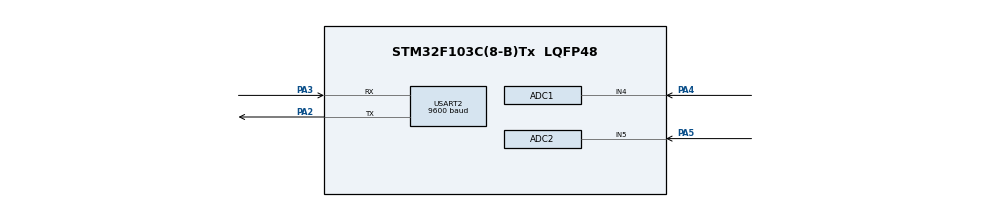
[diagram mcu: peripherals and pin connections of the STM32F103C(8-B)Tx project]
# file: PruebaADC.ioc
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ADC1.Channel-0\#ChannelRegularConversion=ADC_CHANNEL_4
ADC1.ContinuousConvMode=DISABLE
ADC1.DataAlign=ADC_DATAALIGN_RIGHT
ADC1.DiscontinuousConvMode=DISABLE
ADC1.EnableAnalogWatchDog=false
ADC1.EnableRegularConversion=ENABLE
ADC1.ExternalTrigConv=ADC_SOFTWARE_START
ADC1.InjNumberOfConversion=0
ADC1.NbrOfConversion=1
ADC1.NbrOfConversionFlag=1
ADC1.Rank-0\#ChannelRegularConversion=1
ADC1.SamplingTime-0\#ChannelRegularConversion=ADC_SAMPLETIME_1CYCLE_5
ADC1.ScanConvMode=ADC_SCAN_DISABLE
ADC1.master=1
ADC2.Channel-15\#ChannelRegularConversion=ADC_CHANNEL_5
ADC2.NbrOfConversionFlag=1
ADC2.Rank-15\#ChannelRegularConversion=1
ADC2.SamplingTime-15\#ChannelRegularConversion=ADC_SAMPLETIME_1CYCLE_5
Mcu.Family=STM32F1
Mcu.Name=STM32F103C(8-B)Tx
Mcu.Package=LQFP48
NVIC.ADC1_2_IRQn=true\:0\:0\:false\:false\:true\:true
NVIC.PriorityGroup=NVIC_PRIORITYGROUP_4
PA2.Mode=Asynchronous
PA2.Signal=USART2_TX
PA3.Mode=Asynchronous
PA3.Signal=USART2_RX
PA4.Signal=ADCx_IN4
PA5.Signal=ADCx_IN5
ProjectManager.HeapSize=0x200
ProjectManager.StackSize=0x400
ProjectManager.TargetToolchain=MDK-ARM V5
RCC.APB1Freq_Value=8000000
RCC.APB2Freq_Value=8000000
SH.ADCx_IN4.0=ADC1_IN4,IN4
SH.ADCx_IN5.0=ADC2_IN5,IN5
USART2.BaudRate=9600
USART2.VirtualMode=VM_ASYNC
VP_SYS_VS_ND.Mode=No_Debug
board=custom

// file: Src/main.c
#include "main.h"
#include "stm32f1xx_hal.h"

ADC_HandleTypeDef hadc1;
ADC_HandleTypeDef hadc2;

UART_HandleTypeDef huart2;

/* USER CODE BEGIN PV */
/* Private variables ---------------------------------------------------------*/
	char dataOut[100];
	float ADC_Data_1,ADC_Data_2;
/* USER CODE END PV */

void SystemClock_Config(void);
static void MX_GPIO_Init(void);
static void MX_ADC1_Init(void);
static void MX_USART2_UART_Init(void);
static void MX_ADC2_Init(void);

static void SendData (void);

int main(void)
{

  HAL_Init();
  SystemClock_Config();

  MX_GPIO_Init();
  MX_ADC1_Init();
  MX_USART2_UART_Init();
  MX_ADC2_Init();

	HAL_ADC_Start_IT(&hadc1);
	HAL_ADC_Start_IT(&hadc2);

  while (1)
  {
		HAL_ADC_Start_IT(&hadc1);			//Checa CalibraciСn de la constante
		//HAL_ADC_Start_IT(&hadc2);			//Checa CalibraciСn de la constante
		SendData();
		HAL_Delay(250);

  }

}

static void SendData (void){

	sprintf(dataOut,"%2f#", (ADC_Data_1*0.024420024));
	HAL_UART_Transmit(&huart2, dataOut,strlen(dataOut), 100);
}
//ADC Interrupt------------------
	void HAL_ADC_ConvCpltCallback(ADC_HandleTypeDef* hadc){
		if(__HAL_ADC_GET_FLAG(hadc,ADC_FLAG_EOC)){
			ADC_Data_1=HAL_ADC_GetValue(&hadc1);
			//ADC_Data_2=HAL_ADC_GetValue(&hadc2);
		}
	}

void SystemClock_Config(void)
{

  RCC_OscInitTypeDef RCC_OscInitStruct;
  RCC_ClkInitTypeDef RCC_ClkInitStruct;
  RCC_PeriphCLKInitTypeDef PeriphClkInit;

    /**Initializes the CPU, AHB and APB busses clocks
    */
  RCC_OscInitStruct.OscillatorType = RCC_OSCILLATORTYPE_HSI;
  RCC_OscInitStruct.HSIState = RCC_HSI_ON;
  RCC_OscInitStruct.HSICalibrationValue = 16;
  RCC_OscInitStruct.PLL.PLLState = RCC_PLL_NONE;
  if (HAL_RCC_OscConfig(&RCC_OscInitStruct) != HAL_OK)
  {
    _Error_Handler(__FILE__, __LINE__);
  }

    /**Initializes the CPU, AHB and APB busses clocks
    */
  RCC_ClkInitStruct.ClockType = RCC_CLOCKTYPE_HCLK|RCC_CLOCKTYPE_SYSCLK
                              |RCC_CLOCKTYPE_PCLK1|RCC_CLOCKTYPE_PCLK2;
  RCC_ClkInitStruct.SYSCLKSource = RCC_SYSCLKSOURCE_HSI;
  RCC_ClkInitStruct.AHBCLKDivider = RCC_SYSCLK_DIV1;
  RCC_ClkInitStruct.APB1CLKDivider = RCC_HCLK_DIV1;
  RCC_ClkInitStruct.APB2CLKDivider = RCC_HCLK_DIV1;

  if (HAL_RCC_ClockConfig(&RCC_ClkInitStruct, FLASH_LATENCY_0) != HAL_OK)
  {
    _Error_Handler(__FILE__, __LINE__);
  }

  PeriphClkInit.PeriphClockSelection = RCC_PERIPHCLK_ADC;
  PeriphClkInit.AdcClockSelection = RCC_ADCPCLK2_DIV2;
  if (HAL_RCCEx_PeriphCLKConfig(&PeriphClkInit) != HAL_OK)
  {
    _Error_Handler(__FILE__, __LINE__);
  }

    /**Configure the Systick interrupt time
    */
  HAL_SYSTICK_Config(HAL_RCC_GetHCLKFreq()/1000);

    /**Configure the Systick
    */
  HAL_SYSTICK_CLKSourceConfig(SYSTICK_CLKSOURCE_HCLK);

  /* SysTick_IRQn interrupt configuration */
  HAL_NVIC_SetPriority(SysTick_IRQn, 0, 0);
}

/* ADC1 init function */
static void MX_ADC1_Init(void)
{

  ADC_ChannelConfTypeDef sConfig;

    /**Common config
    */
  hadc1.Instance = ADC1;
  hadc1.Init.ScanConvMode = ADC_SCAN_DISABLE;
  hadc1.Init.ContinuousConvMode = DISABLE;
  hadc1.Init.DiscontinuousConvMode = DISABLE;
  hadc1.Init.ExternalTrigConv = ADC_SOFTWARE_START;
  hadc1.Init.DataAlign = ADC_DATAALIGN_RIGHT;
  hadc1.Init.NbrOfConversion = 1;
  if (HAL_ADC_Init(&hadc1) != HAL_OK)
  {
    _Error_Handler(__FILE__, __LINE__);
  }

    /**Configure Regular Channel
    */
  sConfig.Channel = ADC_CHANNEL_4;
  sConfig.Rank = ADC_REGULAR_RANK_1;
  sConfig.SamplingTime = ADC_SAMPLETIME_1CYCLE_5;
  if (HAL_ADC_ConfigChannel(&hadc1, &sConfig) != HAL_OK)
  {
    _Error_Handler(__FILE__, __LINE__);
  }

}

/* ADC2 init function */
static void MX_ADC2_Init(void)
{

  ADC_ChannelConfTypeDef sConfig;

    /**Common config
    */
  hadc2.Instance = ADC2;
  hadc2.Init.ScanConvMode = ADC_SCAN_DISABLE;
  hadc2.Init.ContinuousConvMode = DISABLE;
  hadc2.Init.DiscontinuousConvMode = DISABLE;
  hadc2.Init.ExternalTrigConv = ADC_SOFTWARE_START;
  hadc2.Init.DataAlign = ADC_DATAALIGN_RIGHT;
  hadc2.Init.NbrOfConversion = 1;
  if (HAL_ADC_Init(&hadc2) != HAL_OK)
  {
    _Error_Handler(__FILE__, __LINE__);
  }

    /**Configure Regular Channel
    */
  sConfig.Channel = ADC_CHANNEL_5;
  sConfig.Rank = ADC_REGULAR_RANK_1;
  sConfig.SamplingTime = ADC_SAMPLETIME_1CYCLE_5;
  if (HAL_ADC_ConfigChannel(&hadc2, &sConfig) != HAL_OK)
  {
    _Error_Handler(__FILE__, __LINE__);
  }

}

/* USART2 init function */
static void MX_USART2_UART_Init(void)
{

  huart2.Instance = USART2;
  huart2.Init.BaudRate = 9600;
  huart2.Init.WordLength = UART_WORDLENGTH_8B;
  huart2.Init.StopBits = UART_STOPBITS_1;
  huart2.Init.Parity = UART_PARITY_NONE;
  huart2.Init.Mode = UART_MODE_TX_RX;
  huart2.Init.HwFlowCtl = UART_HWCONTROL_NONE;
  huart2.Init.OverSampling = UART_OVERSAMPLING_16;
  if (HAL_UART_Init(&huart2) != HAL_OK)
  {
    _Error_Handler(__FILE__, __LINE__);
  }

}

/** Pinout Configuration
*/
static void MX_GPIO_Init(void)
{

  /* GPIO Ports Clock Enable */
  __HAL_RCC_GPIOA_CLK_ENABLE();

}

void _Error_Handler(char *file, int line)
{
  while(1)
  {
  }
}

/************************ (C) COPYRIGHT STMicroelectronics *****END OF FILE****/
